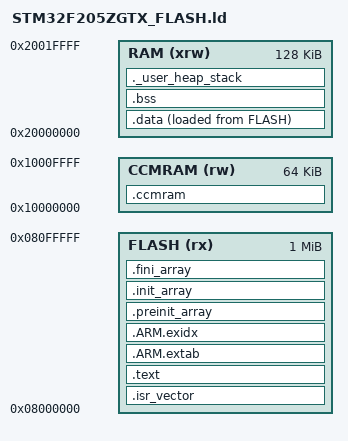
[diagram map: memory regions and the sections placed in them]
/* Linker script for STM32F205ZG (1MB Flash, 128KB RAM) */

MEMORY
{
  FLASH (rx)      : ORIGIN = 0x08000000, LENGTH = 1024K
  RAM (xrw)       : ORIGIN = 0x20000000, LENGTH = 128K
  CCMRAM (rw)     : ORIGIN = 0x10000000, LENGTH = 64K
}

ENTRY(Reset_Handler)

_estack = ORIGIN(RAM) + LENGTH(RAM);

SECTIONS
{
  .isr_vector :
  {
    . = ALIGN(4);
    KEEP(*(.isr_vector))
    . = ALIGN(4);
  } > FLASH

  .text :
  {
    . = ALIGN(4);
    *(.text*)
    *(.rodata*)
    *(.glue_7)
    *(.glue_7t)
    *(.eh_frame)
    . = ALIGN(4);
  } > FLASH

  .ARM.extab   : { *(.ARM.extab* .gnu.linkonce.armextab.*) } > FLASH
  .ARM.exidx   : { *(.ARM.exidx* .gnu.linkonce.armexidx.*) } > FLASH

  .preinit_array :
  {
    PROVIDE_HIDDEN (__preinit_array_start = .);
    KEEP (*(.preinit_array*))
    PROVIDE_HIDDEN (__preinit_array_end = .);
  } > FLASH

  .init_array :
  {
    PROVIDE_HIDDEN (__init_array_start = .);
    KEEP (*(SORT(.init_array.*)))
    KEEP (*(.init_array*))
    PROVIDE_HIDDEN (__init_array_end = .);
  } > FLASH

  .fini_array :
  {
    PROVIDE_HIDDEN (__fini_array_start = .);
    KEEP (*(.fini_array*))
    KEEP (*(SORT(.fini_array.*)))
    PROVIDE_HIDDEN (__fini_array_end = .);
  } > FLASH

  _sidata = LOADADDR(.data);

  .data :
  {
    . = ALIGN(4);
    _sdata = .;
    *(.data*)
    . = ALIGN(4);
    _edata = .;
  } > RAM AT > FLASH

  .ccmram (NOLOAD) :
  {
    . = ALIGN(4);
    _sccmram = .;
    *(.ccmram*)
    . = ALIGN(4);
    _eccmram = .;
  } > CCMRAM

  .bss (NOLOAD) :
  {
    . = ALIGN(4);
    _sbss = .;
    *(.bss*)
    *(COMMON)
    . = ALIGN(4);
    _ebss = .;
  } > RAM

  ._user_heap_stack (NOLOAD) :
  {
    . = ALIGN(8);
    PROVIDE(end = .);
    PROVIDE(_end = .);
    PROVIDE(__end__ = .);
    . = . + _Min_Heap_Size;
    . = . + _Min_Stack_Size;
    . = ALIGN(8);
  } > RAM

  /* Remove information from the standard libraries */
  /DISCARD/ :
  {
    libc.a (*, .*)
    libm.a (*, .*)
    libgcc.a (*, .*)
  }
}

_Min_Heap_Size = 0x200;
_Min_Stack_Size = 0x800;
